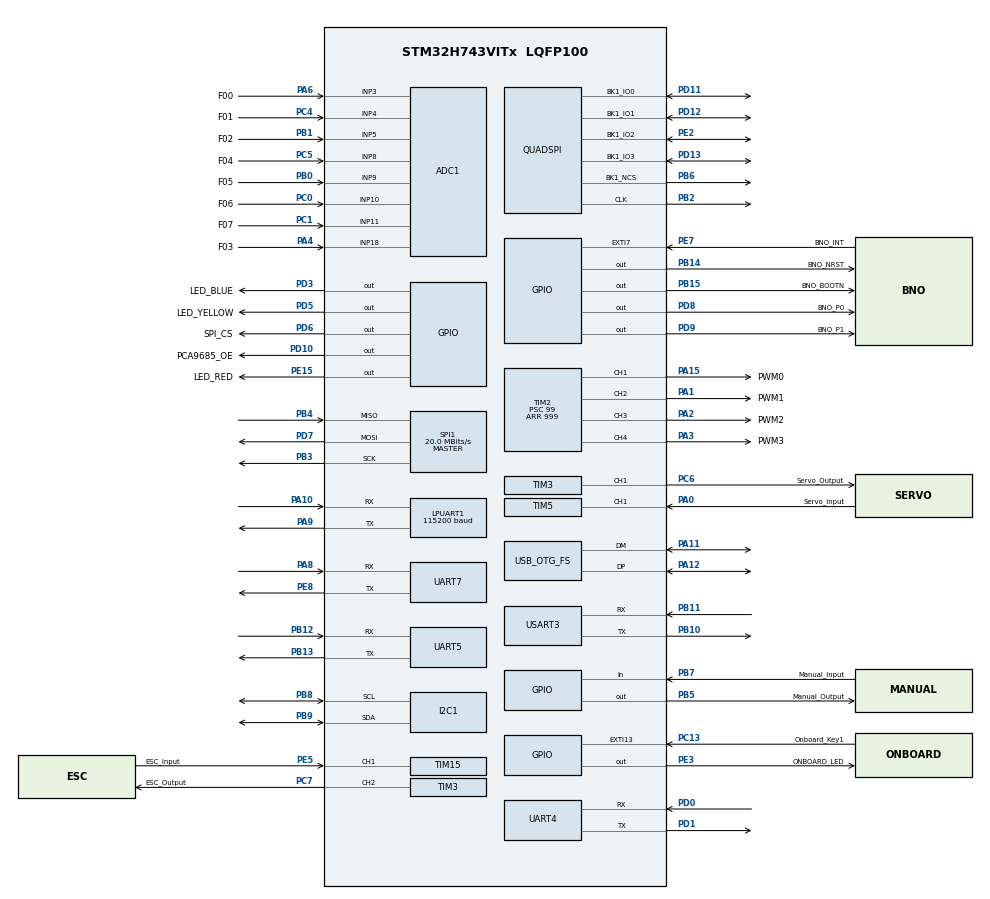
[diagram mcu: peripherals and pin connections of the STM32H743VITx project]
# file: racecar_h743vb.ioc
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ADC1.Channel-0\#ChannelRegularConversion=ADC_CHANNEL_3
ADC1.Channel-1\#ChannelRegularConversion=ADC_CHANNEL_4
ADC1.Channel-2\#ChannelRegularConversion=ADC_CHANNEL_5
ADC1.Channel-3\#ChannelRegularConversion=ADC_CHANNEL_8
ADC1.Channel-4\#ChannelRegularConversion=ADC_CHANNEL_9
ADC1.Channel-5\#ChannelRegularConversion=ADC_CHANNEL_10
ADC1.Channel-6\#ChannelRegularConversion=ADC_CHANNEL_11
ADC1.Channel-7\#ChannelRegularConversion=ADC_CHANNEL_18
ADC1.ClockPrescaler=ADC_CLOCK_ASYNC_DIV64
ADC1.ContinuousConvMode=ENABLE
ADC1.ConversionDataManagement=ADC_CONVERSIONDATA_DMA_CIRCULAR
ADC1.NbrOfConversion=8
ADC1.NbrOfConversionFlag=1
ADC1.OffsetNumber-0\#ChannelRegularConversion=ADC_OFFSET_NONE
ADC1.OffsetNumber-1\#ChannelRegularConversion=ADC_OFFSET_NONE
ADC1.OffsetNumber-2\#ChannelRegularConversion=ADC_OFFSET_NONE
ADC1.OffsetNumber-3\#ChannelRegularConversion=ADC_OFFSET_NONE
ADC1.OffsetNumber-4\#ChannelRegularConversion=ADC_OFFSET_NONE
ADC1.OffsetNumber-5\#ChannelRegularConversion=ADC_OFFSET_NONE
ADC1.OffsetNumber-6\#ChannelRegularConversion=ADC_OFFSET_NONE
ADC1.OffsetNumber-7\#ChannelRegularConversion=ADC_OFFSET_NONE
ADC1.OffsetSignedSaturation-0\#ChannelRegularConversion=DISABLE
ADC1.OffsetSignedSaturation-1\#ChannelRegularConversion=DISABLE
ADC1.OffsetSignedSaturation-2\#ChannelRegularConversion=DISABLE
ADC1.OffsetSignedSaturation-3\#ChannelRegularConversion=DISABLE
ADC1.OffsetSignedSaturation-4\#ChannelRegularConversion=DISABLE
ADC1.OffsetSignedSaturation-5\#ChannelRegularConversion=DISABLE
ADC1.OffsetSignedSaturation-6\#ChannelRegularConversion=DISABLE
ADC1.OffsetSignedSaturation-7\#ChannelRegularConversion=DISABLE
ADC1.Rank-0\#ChannelRegularConversion=1
ADC1.Rank-1\#ChannelRegularConversion=2
ADC1.Rank-2\#ChannelRegularConversion=3
ADC1.Rank-3\#ChannelRegularConversion=4
ADC1.Rank-4\#ChannelRegularConversion=5
ADC1.Rank-5\#ChannelRegularConversion=6
ADC1.Rank-6\#ChannelRegularConversion=7
ADC1.Rank-7\#ChannelRegularConversion=8
ADC1.SamplingTime-0\#ChannelRegularConversion=ADC_SAMPLETIME_387CYCLES_5
ADC1.SamplingTime-1\#ChannelRegularConversion=ADC_SAMPLETIME_387CYCLES_5
ADC1.SamplingTime-2\#ChannelRegularConversion=ADC_SAMPLETIME_387CYCLES_5
ADC1.SamplingTime-3\#ChannelRegularConversion=ADC_SAMPLETIME_387CYCLES_5
ADC1.SamplingTime-4\#ChannelRegularConversion=ADC_SAMPLETIME_387CYCLES_5
ADC1.SamplingTime-5\#ChannelRegularConversion=ADC_SAMPLETIME_387CYCLES_5
ADC1.SamplingTime-6\#ChannelRegularConversion=ADC_SAMPLETIME_387CYCLES_5
ADC1.SamplingTime-7\#ChannelRegularConversion=ADC_SAMPLETIME_387CYCLES_5
ADC1.master=1
Bdma.LPUART1_RX.0.Direction=DMA_PERIPH_TO_MEMORY
Bdma.LPUART1_RX.0.EventEnable=DISABLE
Bdma.LPUART1_RX.0.Instance=BDMA_Channel0
Bdma.LPUART1_RX.0.MemDataAlignment=DMA_MDATAALIGN_BYTE
Bdma.LPUART1_RX.0.MemInc=DMA_MINC_ENABLE
Bdma.LPUART1_RX.0.Mode=DMA_CIRCULAR
Bdma.LPUART1_RX.0.PeriphDataAlignment=DMA_PDATAALIGN_BYTE
Bdma.LPUART1_RX.0.PeriphInc=DMA_PINC_DISABLE
Bdma.LPUART1_RX.0.Polarity=HAL_DMAMUX_REQ_GEN_RISING
Bdma.LPUART1_RX.0.Priority=DMA_PRIORITY_LOW
Bdma.LPUART1_RX.0.RequestNumber=1
Bdma.LPUART1_RX.0.SignalID=NONE
Bdma.LPUART1_RX.0.SyncEnable=DISABLE
Bdma.LPUART1_RX.0.SyncPolarity=HAL_DMAMUX_SYNC_NO_EVENT
Bdma.LPUART1_RX.0.SyncRequestNumber=1
Bdma.LPUART1_RX.0.SyncSignalID=NONE
Bdma.Request0=LPUART1_RX
Bdma.RequestsNb=1
Dma.ADC1.4.Direction=DMA_PERIPH_TO_MEMORY
Dma.ADC1.4.EventEnable=DISABLE
Dma.ADC1.4.FIFOMode=DMA_FIFOMODE_DISABLE
Dma.ADC1.4.Instance=DMA1_Stream4
Dma.ADC1.4.MemDataAlignment=DMA_MDATAALIGN_HALFWORD
Dma.ADC1.4.MemInc=DMA_MINC_ENABLE
Dma.ADC1.4.Mode=DMA_CIRCULAR
Dma.ADC1.4.PeriphDataAlignment=DMA_PDATAALIGN_HALFWORD
Dma.ADC1.4.PeriphInc=DMA_PINC_DISABLE
Dma.ADC1.4.Polarity=HAL_DMAMUX_REQ_GEN_RISING
Dma.ADC1.4.Priority=DMA_PRIORITY_LOW
Dma.ADC1.4.RequestNumber=1
Dma.ADC1.4.SignalID=NONE
Dma.ADC1.4.SyncEnable=DISABLE
Dma.ADC1.4.SyncPolarity=HAL_DMAMUX_SYNC_NO_EVENT
Dma.ADC1.4.SyncRequestNumber=1
Dma.ADC1.4.SyncSignalID=NONE
Dma.Request0=UART4_RX
Dma.Request1=UART4_TX
Dma.Request2=UART5_RX
Dma.Request3=UART7_RX
Dma.Request4=ADC1
Dma.UART4_RX.0.Direction=DMA_PERIPH_TO_MEMORY
Dma.UART4_RX.0.EventEnable=DISABLE
Dma.UART4_RX.0.FIFOMode=DMA_FIFOMODE_DISABLE
Dma.UART4_RX.0.Instance=DMA1_Stream0
Dma.UART4_RX.0.MemDataAlignment=DMA_MDATAALIGN_BYTE
Dma.UART4_RX.0.MemInc=DMA_MINC_ENABLE
Dma.UART4_RX.0.Mode=DMA_NORMAL
Dma.UART4_RX.0.PeriphDataAlignment=DMA_PDATAALIGN_BYTE
Dma.UART4_RX.0.PeriphInc=DMA_PINC_DISABLE
Dma.UART4_RX.0.Polarity=HAL_DMAMUX_REQ_GEN_RISING
Dma.UART4_RX.0.Priority=DMA_PRIORITY_LOW
Dma.UART4_RX.0.RequestNumber=1
Dma.UART4_RX.0.SignalID=NONE
Dma.UART4_RX.0.SyncEnable=DISABLE
Dma.UART4_RX.0.SyncPolarity=HAL_DMAMUX_SYNC_NO_EVENT
Dma.UART4_RX.0.SyncRequestNumber=1
Dma.UART4_RX.0.SyncSignalID=NONE
Dma.UART4_TX.1.Direction=DMA_MEMORY_TO_PERIPH
Dma.UART4_TX.1.EventEnable=DISABLE
Dma.UART4_TX.1.FIFOMode=DMA_FIFOMODE_DISABLE
Dma.UART4_TX.1.Instance=DMA1_Stream1
Dma.UART4_TX.1.MemDataAlignment=DMA_MDATAALIGN_BYTE
Dma.UART4_TX.1.MemInc=DMA_MINC_ENABLE
Dma.UART4_TX.1.Mode=DMA_NORMAL
Dma.UART4_TX.1.PeriphDataAlignment=DMA_PDATAALIGN_BYTE
Dma.UART4_TX.1.PeriphInc=DMA_PINC_DISABLE
Dma.UART4_TX.1.Polarity=HAL_DMAMUX_REQ_GEN_RISING
Dma.UART4_TX.1.Priority=DMA_PRIORITY_LOW
Dma.UART4_TX.1.RequestNumber=1
Dma.UART4_TX.1.SignalID=NONE
Dma.UART4_TX.1.SyncEnable=DISABLE
Dma.UART4_TX.1.SyncPolarity=HAL_DMAMUX_SYNC_NO_EVENT
Dma.UART4_TX.1.SyncRequestNumber=1
Dma.UART4_TX.1.SyncSignalID=NONE
Dma.UART5_RX.2.Direction=DMA_PERIPH_TO_MEMORY
Dma.UART5_RX.2.EventEnable=DISABLE
Dma.UART5_RX.2.FIFOMode=DMA_FIFOMODE_DISABLE
Dma.UART5_RX.2.Instance=DMA1_Stream2
Dma.UART5_RX.2.MemDataAlignment=DMA_MDATAALIGN_BYTE
Dma.UART5_RX.2.MemInc=DMA_MINC_ENABLE
Dma.UART5_RX.2.Mode=DMA_CIRCULAR
Dma.UART5_RX.2.PeriphDataAlignment=DMA_PDATAALIGN_BYTE
Dma.UART5_RX.2.PeriphInc=DMA_PINC_DISABLE
Dma.UART5_RX.2.Polarity=HAL_DMAMUX_REQ_GEN_RISING
Dma.UART5_RX.2.Priority=DMA_PRIORITY_LOW
Dma.UART5_RX.2.RequestNumber=1
Dma.UART5_RX.2.SignalID=NONE
Dma.UART5_RX.2.SyncEnable=DISABLE
Dma.UART5_RX.2.SyncPolarity=HAL_DMAMUX_SYNC_NO_EVENT
Dma.UART5_RX.2.SyncRequestNumber=1
Dma.UART5_RX.2.SyncSignalID=NONE
Dma.UART7_RX.3.Direction=DMA_PERIPH_TO_MEMORY
Dma.UART7_RX.3.EventEnable=DISABLE
Dma.UART7_RX.3.FIFOMode=DMA_FIFOMODE_DISABLE
Dma.UART7_RX.3.Instance=DMA1_Stream3
Dma.UART7_RX.3.MemDataAlignment=DMA_MDATAALIGN_BYTE
Dma.UART7_RX.3.MemInc=DMA_MINC_ENABLE
Dma.UART7_RX.3.Mode=DMA_NORMAL
Dma.UART7_RX.3.PeriphDataAlignment=DMA_PDATAALIGN_BYTE
Dma.UART7_RX.3.PeriphInc=DMA_PINC_DISABLE
Dma.UART7_RX.3.Polarity=HAL_DMAMUX_REQ_GEN_RISING
Dma.UART7_RX.3.Priority=DMA_PRIORITY_LOW
Dma.UART7_RX.3.RequestNumber=1
Dma.UART7_RX.3.SignalID=NONE
Dma.UART7_RX.3.SyncEnable=DISABLE
Dma.UART7_RX.3.SyncPolarity=HAL_DMAMUX_SYNC_NO_EVENT
Dma.UART7_RX.3.SyncRequestNumber=1
Dma.UART7_RX.3.SyncSignalID=NONE
I2C1.Timing=0x00C0EAFF
LPUART1.BaudRate=115200
Mcu.Family=STM32H7
Mcu.Name=STM32H743VITx
Mcu.Package=LQFP100
NVIC.ADC_IRQn=true\:0\:0\:false\:false\:true\:true\:true\:true
NVIC.BDMA_Channel0_IRQn=true\:0\:0\:false\:false\:true\:false\:true\:true
NVIC.DMA1_Stream0_IRQn=true\:0\:0\:false\:false\:true\:false\:true\:true
NVIC.DMA1_Stream1_IRQn=true\:0\:0\:false\:false\:true\:false\:true\:true
NVIC.DMA1_Stream2_IRQn=true\:0\:0\:false\:false\:true\:false\:true\:true
NVIC.DMA1_Stream3_IRQn=true\:0\:0\:false\:false\:true\:false\:true\:true
NVIC.DMA1_Stream4_IRQn=true\:0\:0\:false\:false\:true\:false\:true\:true
NVIC.LPUART1_IRQn=true\:0\:0\:false\:false\:true\:true\:true\:true
NVIC.PriorityGroup=NVIC_PRIORITYGROUP_4
NVIC.TIM16_IRQn=true\:0\:0\:false\:false\:true\:true\:true\:true
NVIC.TIM7_IRQn=true\:0\:0\:false\:false\:true\:true\:true\:true
NVIC.UART4_IRQn=true\:0\:0\:false\:false\:true\:true\:true\:true
NVIC.UART5_IRQn=true\:0\:0\:false\:false\:true\:true\:true\:true
NVIC.UART7_IRQn=true\:0\:0\:false\:false\:true\:true\:true\:true
PA0.GPIO_Label=Servo_Input
PA0.Signal=S_TIM5_CH1
PA1.GPIO_Label=PWM1
PA1.Signal=S_TIM2_CH2
PA10.Mode=Asynchronous
PA10.Signal=LPUART1_RX
PA11.Mode=Device_Only
PA11.Signal=USB_OTG_FS_DM
PA12.Mode=Device_Only
PA12.Signal=USB_OTG_FS_DP
PA13\ (JTMS/SWDIO).Mode=Serial_Wire
PA13\ (JTMS/SWDIO).Signal=DEBUG_JTMS-SWDIO
PA14\ (JTCK/SWCLK).Mode=Serial_Wire
PA14\ (JTCK/SWCLK).Signal=DEBUG_JTCK-SWCLK
PA15\ (JTDI).GPIO_Label=PWM0
PA15\ (JTDI).Signal=S_TIM2_CH1_ETR
PA2.GPIO_Label=PWM2
PA2.Signal=S_TIM2_CH3
PA3.GPIO_Label=PWM3
PA3.Signal=S_TIM2_CH4
PA4.GPIO_Label=F03
PA4.Signal=ADCx_INP18
PA6.GPIO_Label=F00
PA6.Signal=ADCx_INP3
PA8.Mode=Asynchronous
PA8.Signal=UART7_RX
PA9.Mode=Asynchronous
PA9.Signal=LPUART1_TX
PB0.GPIO_Label=F05
PB0.Signal=ADCx_INP9
PB1.GPIO_Label=F02
PB1.Signal=ADCx_INP5
PB10.Mode=Asynchronous
PB10.Signal=USART3_TX
PB11.Mode=Asynchronous
PB11.Signal=USART3_RX
PB12.Mode=Asynchronous
PB12.Signal=UART5_RX
PB13.Mode=Asynchronous
PB13.Signal=UART5_TX
PB14.GPIO_Label=BNO_NRST
PB14.Signal=GPIO_Output
PB15.GPIO_Label=BNO_BOOTN
PB15.Signal=GPIO_Output
PB2.Mode=Single Bank 1
PB2.Signal=QUADSPI_CLK
PB3\ (JTDO/TRACESWO).Mode=Full_Duplex_Master
PB3\ (JTDO/TRACESWO).Signal=SPI1_SCK
PB4\ (NJTRST).Mode=Full_Duplex_Master
PB4\ (NJTRST).Signal=SPI1_MISO
PB5.GPIO_Label=Manual_Output
PB5.Signal=GPIO_Output
PB6.Mode=Single Bank 1
PB6.Signal=QUADSPI_BK1_NCS
PB7.GPIO_Label=Manual_Input
PB7.Signal=GPIO_Input
PB8.Mode=I2C
PB8.Signal=I2C1_SCL
PB9.Mode=I2C
PB9.Signal=I2C1_SDA
PC0.GPIO_Label=F06
PC0.Signal=ADCx_INP10
PC1.GPIO_Label=F07
PC1.Signal=ADCx_INP11
PC13.GPIO_Label=Onboard_Key1
PC13.Signal=GPXTI13
PC14-OSC32_IN\ (OSC32_IN).Mode=LSE-External-Oscillator
PC14-OSC32_IN\ (OSC32_IN).Signal=RCC_OSC32_IN
PC15-OSC32_OUT\ (OSC32_OUT).Mode=LSE-External-Oscillator
PC15-OSC32_OUT\ (OSC32_OUT).Signal=RCC_OSC32_OUT
PC4.GPIO_Label=F01
PC4.Signal=ADCx_INP4
PC5.GPIO_Label=F04
PC5.Signal=ADCx_INP8
PC6.GPIO_Label=Servo_Output
PC6.Signal=S_TIM3_CH1
PC7.GPIO_Label=ESC_Output
PC7.Signal=S_TIM3_CH2
PD0.Mode=Asynchronous
PD0.Signal=UART4_RX
PD1.Mode=Asynchronous
PD1.Signal=UART4_TX
PD10.GPIO_Label=PCA9685_OE
PD10.Signal=GPIO_Output
PD11.Mode=Single Bank 1
PD11.Signal=QUADSPI_BK1_IO0
PD12.Mode=Single Bank 1
PD12.Signal=QUADSPI_BK1_IO1
PD13.Mode=Single Bank 1
PD13.Signal=QUADSPI_BK1_IO3
PD3.GPIO_Label=LED_BLUE
PD3.Signal=GPIO_Output
PD5.GPIO_Label=LED_YELLOW
PD5.Signal=GPIO_Output
PD6.GPIO_Label=SPI_CS
PD6.Signal=GPIO_Output
PD7.Mode=Full_Duplex_Master
PD7.Signal=SPI1_MOSI
PD8.GPIO_Label=BNO_P0
PD8.Signal=GPIO_Output
PD9.GPIO_Label=BNO_P1
PD9.Signal=GPIO_Output
PE15.GPIO_Label=LED_RED
PE15.Signal=GPIO_Output
PE2.Mode=Single Bank 1
PE2.Signal=QUADSPI_BK1_IO2
PE3.GPIO_Label=ONBOARD_LED
PE3.Signal=GPIO_Output
PE5.GPIO_Label=ESC_Input
PE5.Signal=S_TIM15_CH1
PE7.GPIO_Label=BNO_INT
PE7.Signal=GPXTI7
PE8.Mode=Asynchronous
PE8.Signal=UART7_TX
PH0-OSC_IN\ (PH0).Mode=HSE-External-Oscillator
PH0-OSC_IN\ (PH0).Signal=RCC_OSC_IN
PH1-OSC_OUT\ (PH1).Mode=HSE-External-Oscillator
PH1-OSC_OUT\ (PH1).Signal=RCC_OSC_OUT
ProjectManager.HeapSize=0x200
ProjectManager.StackSize=0x400
ProjectManager.TargetToolchain=STM32CubeIDE
QUADSPI.ChipSelectHighTime=QSPI_CS_HIGH_TIME_5_CYCLE
QUADSPI.ClockPrescaler=10
QUADSPI.FlashSize=22
QUADSPI.SampleShifting=QSPI_SAMPLE_SHIFTING_HALFCYCLE
RCC.ADCCLockSelection=RCC_ADCCLKSOURCE_CLKP
RCC.ADCFreq_Value=64000000
RCC.APB1Freq_Value=50000000
RCC.APB2Freq_Value=100000000
RCC.APB3Freq_Value=100000000
RCC.APB4Freq_Value=50000000
RCC.CortexFreq_Value=400000000
RCC.D1PPRE=RCC_APB3_DIV2
RCC.D2PPRE1=RCC_APB1_DIV4
RCC.D2PPRE2=RCC_APB2_DIV2
RCC.D3PPRE=RCC_APB4_DIV4
RCC.DIVM1=5
RCC.DIVM2=10
RCC.DIVN1=160
RCC.DIVN2=60
RCC.DIVN3=128
RCC.DIVQ1=20
RCC.DIVQ2=4
RCC.HCLKFreq_Value=200000000
RCC.HPRE=RCC_HCLK_DIV2
RCC.PLL2FRACN=0
RCC.PLL2_VCI_Range-AdvancedSettings=RCC_PLL2VCIRANGE_0
RCC.PLL3FRACN=0
RCC.PLL3_VCI_Range-AdvancedSettings=RCC_PLL3VCIRANGE_3
RCC.PLLFRACN=0
RCC.PLLSourceVirtual=RCC_PLLSOURCE_HSE
RCC.SDMMC1CLockSelection=RCC_SDMMCCLKSOURCE_PLL2
RCC.SYSCLKFreq_VALUE=400000000
RCC.SYSCLKSource=RCC_SYSCLKSOURCE_PLLCLK
RCC.Tim2Mul=1
RCC.USBFreq_Value=40000000
SH.ADCx_INP10.0=ADC1_INP10,IN10-Single-Ended
SH.ADCx_INP11.0=ADC1_INP11,IN11-Single-Ended
SH.ADCx_INP18.0=ADC1_INP18,IN18-Single-Ended
SH.ADCx_INP3.0=ADC1_INP3,IN3-Single-Ended
SH.ADCx_INP4.0=ADC1_INP4,IN4-Single-Ended
SH.ADCx_INP5.0=ADC1_INP5,IN5-Single-Ended
SH.ADCx_INP8.0=ADC1_INP8,IN8-Single-Ended
SH.ADCx_INP9.0=ADC1_INP9,IN9-Single-Ended
SH.S_TIM15_CH1.0=TIM15_CH1,PWM_Input_1
SH.S_TIM2_CH1_ETR.0=TIM2_CH1,PWM Generation1 CH1
SH.S_TIM2_CH2.0=TIM2_CH2,PWM Generation2 CH2
SH.S_TIM2_CH3.0=TIM2_CH3,PWM Generation3 CH3
SH.S_TIM2_CH4.0=TIM2_CH4,PWM Generation4 CH4
SH.S_TIM3_CH1.0=TIM3_CH1,PWM Generation1 CH1
SH.S_TIM3_CH2.0=TIM3_CH2,PWM Generation2 CH2
SH.S_TIM5_CH1.0=TIM5_CH1,PWM_Input_1
SPI1.BaudRatePrescaler=SPI_BAUDRATEPRESCALER_2
SPI1.CalculateBaudRate=20.0 MBits/s
SPI1.Direction=SPI_DIRECTION_2LINES
SPI1.Mode=SPI_MODE_MASTER
SPI1.VirtualType=VM_MASTER
TIM16.AutoReloadPreload=TIM_AUTORELOAD_PRELOAD_ENABLE
TIM16.Period=499
TIM16.Prescaler=9999
TIM2.Channel-PWM\ Generation1\ CH1=TIM_CHANNEL_1
TIM2.Channel-PWM\ Generation2\ CH2=TIM_CHANNEL_2
TIM2.Channel-PWM\ Generation3\ CH3=TIM_CHANNEL_3
TIM2.Channel-PWM\ Generation4\ CH4=TIM_CHANNEL_4
TIM2.Period=999
TIM2.Prescaler=99
TIM3.AutoReloadPreload=TIM_AUTORELOAD_PRELOAD_ENABLE
TIM3.Channel-PWM\ Generation1\ CH1=TIM_CHANNEL_1
TIM3.Channel-PWM\ Generation2\ CH2=TIM_CHANNEL_2
TIM3.Period=15503
TIM3.Prescaler=99
TIM7.AutoReloadPreload=TIM_AUTORELOAD_PRELOAD_ENABLE
TIM7.Period=999
TIM7.Prescaler=9999
USART3.VirtualMode-Asynchronous=VM_ASYNC
USB_OTG_FS.VirtualMode=Device_Only
VP_TIM16_VS_ClockSourceINT.Mode=Enable_Timer
VP_TIM7_VS_ClockSourceINT.Mode=Enable_Timer
board=custom

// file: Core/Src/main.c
/* USER CODE BEGIN Header */
/**
  ******************************************************************************
  * @file           : main.c
  * @brief          : Main program body
  ******************************************************************************
  * @attention
  *
  * Copyright (c) 2023 STMicroelectronics.
  * All rights reserved.
  *
  * This software is licensed under terms that can be found in the LICENSE file
  * in the root directory of this software component.
  * If no LICENSE file comes with this software, it is provided AS-IS.
  *
  ******************************************************************************
  */
/* USER CODE END Header */
#include "main.h"

/* USER CODE BEGIN Includes */
#include "mainpp.h"
/* USER CODE END Includes */

ADC_HandleTypeDef hadc1;
DMA_HandleTypeDef hdma_adc1;

I2C_HandleTypeDef hi2c1;

UART_HandleTypeDef hlpuart1;
UART_HandleTypeDef huart4;
UART_HandleTypeDef huart5;
UART_HandleTypeDef huart7;
UART_HandleTypeDef huart3;
DMA_HandleTypeDef hdma_lpuart1_rx;
DMA_HandleTypeDef hdma_uart4_rx;
DMA_HandleTypeDef hdma_uart4_tx;
DMA_HandleTypeDef hdma_uart5_rx;
DMA_HandleTypeDef hdma_uart7_rx;

QSPI_HandleTypeDef hqspi;

SPI_HandleTypeDef hspi1;

TIM_HandleTypeDef htim2;
TIM_HandleTypeDef htim3;
TIM_HandleTypeDef htim5;
TIM_HandleTypeDef htim7;
TIM_HandleTypeDef htim15;
TIM_HandleTypeDef htim16;

PCD_HandleTypeDef hpcd_USB_OTG_FS;

void SystemClock_Config(void);
void PeriphCommonClock_Config(void);
static void MX_GPIO_Init(void);
static void MX_BDMA_Init(void);
static void MX_DMA_Init(void);
static void MX_ADC1_Init(void);
static void MX_I2C1_Init(void);
static void MX_LPUART1_UART_Init(void);
static void MX_UART4_Init(void);
static void MX_UART5_Init(void);
static void MX_UART7_Init(void);
static void MX_USART3_UART_Init(void);
static void MX_QUADSPI_Init(void);
static void MX_SPI1_Init(void);
static void MX_TIM5_Init(void);
static void MX_TIM2_Init(void);
static void MX_USB_OTG_FS_PCD_Init(void);
static void MX_TIM3_Init(void);
static void MX_TIM15_Init(void);
static void MX_TIM7_Init(void);
static void MX_TIM16_Init(void);

int main(void)
{

  /* MCU Configuration--------------------------------------------------------*/

  /* Reset of all peripherals, Initializes the Flash interface and the Systick. */
  HAL_Init();

  /* Configure the system clock */
  SystemClock_Config();

/* Configure the peripherals common clocks */
  PeriphCommonClock_Config();

  /* Initialize all configured peripherals */
  MX_GPIO_Init();
  MX_BDMA_Init();
  MX_DMA_Init();
  MX_ADC1_Init();
  MX_I2C1_Init();
  MX_LPUART1_UART_Init();
  MX_UART4_Init();
  MX_UART5_Init();
  MX_UART7_Init();
  MX_USART3_UART_Init();
  MX_QUADSPI_Init();
  MX_SPI1_Init();
  MX_TIM5_Init();
  MX_TIM2_Init();
  MX_USB_OTG_FS_PCD_Init();
  MX_TIM3_Init();
  MX_TIM15_Init();
  MX_TIM7_Init();
  MX_TIM16_Init();
  /* USER CODE BEGIN 2 */

  setup();
  /* USER CODE END 2 */

  /* Infinite loop */
  /* USER CODE BEGIN WHILE */
  while (1)
  {
	  loop();
    /* USER CODE END WHILE */

  }
}

void SystemClock_Config(void)
{
  RCC_OscInitTypeDef RCC_OscInitStruct = {0};
  RCC_ClkInitTypeDef RCC_ClkInitStruct = {0};

  /** Supply configuration update enable
  */
  HAL_PWREx_ConfigSupply(PWR_LDO_SUPPLY);

  /** Configure the main internal regulator output voltage
  */
  __HAL_PWR_VOLTAGESCALING_CONFIG(PWR_REGULATOR_VOLTAGE_SCALE1);

  while(!__HAL_PWR_GET_FLAG(PWR_FLAG_VOSRDY)) {}

  /** Initializes the RCC Oscillators according to the specified parameters
  * in the RCC_OscInitTypeDef structure.
  */
  RCC_OscInitStruct.OscillatorType = RCC_OSCILLATORTYPE_HSI|RCC_OSCILLATORTYPE_HSE;
  RCC_OscInitStruct.HSEState = RCC_HSE_ON;
  RCC_OscInitStruct.HSIState = RCC_HSI_DIV1;
  RCC_OscInitStruct.HSICalibrationValue = RCC_HSICALIBRATION_DEFAULT;
  RCC_OscInitStruct.PLL.PLLState = RCC_PLL_ON;
  RCC_OscInitStruct.PLL.PLLSource = RCC_PLLSOURCE_HSE;
  RCC_OscInitStruct.PLL.PLLM = 5;
  RCC_OscInitStruct.PLL.PLLN = 160;
  RCC_OscInitStruct.PLL.PLLP = 2;
  RCC_OscInitStruct.PLL.PLLQ = 20;
  RCC_OscInitStruct.PLL.PLLR = 2;
  RCC_OscInitStruct.PLL.PLLRGE = RCC_PLL1VCIRANGE_2;
  RCC_OscInitStruct.PLL.PLLVCOSEL = RCC_PLL1VCOWIDE;
  RCC_OscInitStruct.PLL.PLLFRACN = 0;
  if (HAL_RCC_OscConfig(&RCC_OscInitStruct) != HAL_OK)
  {
    Error_Handler();
  }

  /** Initializes the CPU, AHB and APB buses clocks
  */
  RCC_ClkInitStruct.ClockType = RCC_CLOCKTYPE_HCLK|RCC_CLOCKTYPE_SYSCLK
                              |RCC_CLOCKTYPE_PCLK1|RCC_CLOCKTYPE_PCLK2
                              |RCC_CLOCKTYPE_D3PCLK1|RCC_CLOCKTYPE_D1PCLK1;
  RCC_ClkInitStruct.SYSCLKSource = RCC_SYSCLKSOURCE_PLLCLK;
  RCC_ClkInitStruct.SYSCLKDivider = RCC_SYSCLK_DIV1;
  RCC_ClkInitStruct.AHBCLKDivider = RCC_HCLK_DIV2;
  RCC_ClkInitStruct.APB3CLKDivider = RCC_APB3_DIV2;
  RCC_ClkInitStruct.APB1CLKDivider = RCC_APB1_DIV4;
  RCC_ClkInitStruct.APB2CLKDivider = RCC_APB2_DIV2;
  RCC_ClkInitStruct.APB4CLKDivider = RCC_APB4_DIV4;

  if (HAL_RCC_ClockConfig(&RCC_ClkInitStruct, FLASH_LATENCY_2) != HAL_OK)
  {
    Error_Handler();
  }
}

void PeriphCommonClock_Config(void)
{
  RCC_PeriphCLKInitTypeDef PeriphClkInitStruct = {0};

  /** Initializes the peripherals clock
  */
  PeriphClkInitStruct.PeriphClockSelection = RCC_PERIPHCLK_CKPER;
  PeriphClkInitStruct.CkperClockSelection = RCC_CLKPSOURCE_HSI;
  if (HAL_RCCEx_PeriphCLKConfig(&PeriphClkInitStruct) != HAL_OK)
  {
    Error_Handler();
  }
}

static void MX_ADC1_Init(void)
{

  ADC_MultiModeTypeDef multimode = {0};
  ADC_ChannelConfTypeDef sConfig = {0};

  /** Common config
  */
  hadc1.Instance = ADC1;
  hadc1.Init.ClockPrescaler = ADC_CLOCK_ASYNC_DIV64;
  hadc1.Init.Resolution = ADC_RESOLUTION_16B;
  hadc1.Init.ScanConvMode = ADC_SCAN_ENABLE;
  hadc1.Init.EOCSelection = ADC_EOC_SINGLE_CONV;
  hadc1.Init.LowPowerAutoWait = DISABLE;
  hadc1.Init.ContinuousConvMode = ENABLE;
  hadc1.Init.NbrOfConversion = 8;
  hadc1.Init.DiscontinuousConvMode = DISABLE;
  hadc1.Init.ExternalTrigConv = ADC_SOFTWARE_START;
  hadc1.Init.ExternalTrigConvEdge = ADC_EXTERNALTRIGCONVEDGE_NONE;
  hadc1.Init.ConversionDataManagement = ADC_CONVERSIONDATA_DMA_CIRCULAR;
  hadc1.Init.Overrun = ADC_OVR_DATA_PRESERVED;
  hadc1.Init.LeftBitShift = ADC_LEFTBITSHIFT_NONE;
  hadc1.Init.OversamplingMode = DISABLE;
  if (HAL_ADC_Init(&hadc1) != HAL_OK)
  {
    Error_Handler();
  }

  /** Configure the ADC multi-mode
  */
  multimode.Mode = ADC_MODE_INDEPENDENT;
  if (HAL_ADCEx_MultiModeConfigChannel(&hadc1, &multimode) != HAL_OK)
  {
    Error_Handler();
  }

  /** Configure Regular Channel
  */
  sConfig.Channel = ADC_CHANNEL_3;
  sConfig.Rank = ADC_REGULAR_RANK_1;
  sConfig.SamplingTime = ADC_SAMPLETIME_387CYCLES_5;
  sConfig.SingleDiff = ADC_SINGLE_ENDED;
  sConfig.OffsetNumber = ADC_OFFSET_NONE;
  sConfig.Offset = 0;
  sConfig.OffsetSignedSaturation = DISABLE;
  if (HAL_ADC_ConfigChannel(&hadc1, &sConfig) != HAL_OK)
  {
    Error_Handler();
  }

  /** Configure Regular Channel
  */
  sConfig.Channel = ADC_CHANNEL_4;
  sConfig.Rank = ADC_REGULAR_RANK_2;
  if (HAL_ADC_ConfigChannel(&hadc1, &sConfig) != HAL_OK)
  {
    Error_Handler();
  }

  /** Configure Regular Channel
  */
  sConfig.Channel = ADC_CHANNEL_5;
  sConfig.Rank = ADC_REGULAR_RANK_3;
  if (HAL_ADC_ConfigChannel(&hadc1, &sConfig) != HAL_OK)
  {
    Error_Handler();
  }

  /** Configure Regular Channel
  */
  sConfig.Channel = ADC_CHANNEL_8;
  sConfig.Rank = ADC_REGULAR_RANK_4;
  if (HAL_ADC_ConfigChannel(&hadc1, &sConfig) != HAL_OK)
  {
    Error_Handler();
  }

  /** Configure Regular Channel
  */
  sConfig.Channel = ADC_CHANNEL_9;
  sConfig.Rank = ADC_REGULAR_RANK_5;
  if (HAL_ADC_ConfigChannel(&hadc1, &sConfig) != HAL_OK)
  {
    Error_Handler();
  }

  /** Configure Regular Channel
  */
  sConfig.Channel = ADC_CHANNEL_10;
  sConfig.Rank = ADC_REGULAR_RANK_6;
  if (HAL_ADC_ConfigChannel(&hadc1, &sConfig) != HAL_OK)
  {
    Error_Handler();
  }

  /** Configure Regular Channel
  */
  sConfig.Channel = ADC_CHANNEL_11;
  sConfig.Rank = ADC_REGULAR_RANK_7;
  if (HAL_ADC_ConfigChannel(&hadc1, &sConfig) != HAL_OK)
  {
    Error_Handler();
  }

  /** Configure Regular Channel
  */
  sConfig.Channel = ADC_CHANNEL_18;
  sConfig.Rank = ADC_REGULAR_RANK_8;
  if (HAL_ADC_ConfigChannel(&hadc1, &sConfig) != HAL_OK)
  {
    Error_Handler();
  }

}

static void MX_I2C1_Init(void)
{

  hi2c1.Instance = I2C1;
  hi2c1.Init.Timing = 0x00C0EAFF;
  hi2c1.Init.OwnAddress1 = 0;
  hi2c1.Init.AddressingMode = I2C_ADDRESSINGMODE_7BIT;
  hi2c1.Init.DualAddressMode = I2C_DUALADDRESS_DISABLE;
  hi2c1.Init.OwnAddress2 = 0;
  hi2c1.Init.OwnAddress2Masks = I2C_OA2_NOMASK;
  hi2c1.Init.GeneralCallMode = I2C_GENERALCALL_DISABLE;
  hi2c1.Init.NoStretchMode = I2C_NOSTRETCH_DISABLE;
  if (HAL_I2C_Init(&hi2c1) != HAL_OK)
  {
    Error_Handler();
  }

  /** Configure Analogue filter
  */
  if (HAL_I2CEx_ConfigAnalogFilter(&hi2c1, I2C_ANALOGFILTER_ENABLE) != HAL_OK)
  {
    Error_Handler();
  }

  /** Configure Digital filter
  */
  if (HAL_I2CEx_ConfigDigitalFilter(&hi2c1, 0) != HAL_OK)
  {
    Error_Handler();
  }

}

static void MX_LPUART1_UART_Init(void)
{

  hlpuart1.Instance = LPUART1;
  hlpuart1.Init.BaudRate = 115200;
  hlpuart1.Init.WordLength = UART_WORDLENGTH_8B;
  hlpuart1.Init.StopBits = UART_STOPBITS_1;
  hlpuart1.Init.Parity = UART_PARITY_NONE;
  hlpuart1.Init.Mode = UART_MODE_TX_RX;
  hlpuart1.Init.HwFlowCtl = UART_HWCONTROL_NONE;
  hlpuart1.Init.OneBitSampling = UART_ONE_BIT_SAMPLE_DISABLE;
  hlpuart1.Init.ClockPrescaler = UART_PRESCALER_DIV1;
  hlpuart1.AdvancedInit.AdvFeatureInit = UART_ADVFEATURE_NO_INIT;
  hlpuart1.FifoMode = UART_FIFOMODE_DISABLE;
  if (HAL_UART_Init(&hlpuart1) != HAL_OK)
  {
    Error_Handler();
  }
  if (HAL_UARTEx_SetTxFifoThreshold(&hlpuart1, UART_TXFIFO_THRESHOLD_1_8) != HAL_OK)
  {
    Error_Handler();
  }
  if (HAL_UARTEx_SetRxFifoThreshold(&hlpuart1, UART_RXFIFO_THRESHOLD_1_8) != HAL_OK)
  {
    Error_Handler();
  }
  if (HAL_UARTEx_DisableFifoMode(&hlpuart1) != HAL_OK)
  {
    Error_Handler();
  }

}

static void MX_UART4_Init(void)
{

  huart4.Instance = UART4;
  huart4.Init.BaudRate = 115200;
  huart4.Init.WordLength = UART_WORDLENGTH_8B;
  huart4.Init.StopBits = UART_STOPBITS_1;
  huart4.Init.Parity = UART_PARITY_NONE;
  huart4.Init.Mode = UART_MODE_TX_RX;
  huart4.Init.HwFlowCtl = UART_HWCONTROL_NONE;
  huart4.Init.OverSampling = UART_OVERSAMPLING_16;
  huart4.Init.OneBitSampling = UART_ONE_BIT_SAMPLE_DISABLE;
  huart4.Init.ClockPrescaler = UART_PRESCALER_DIV1;
  huart4.AdvancedInit.AdvFeatureInit = UART_ADVFEATURE_NO_INIT;
  if (HAL_UART_Init(&huart4) != HAL_OK)
  {
    Error_Handler();
  }
  if (HAL_UARTEx_SetTxFifoThreshold(&huart4, UART_TXFIFO_THRESHOLD_1_8) != HAL_OK)
  {
    Error_Handler();
  }
  if (HAL_UARTEx_SetRxFifoThreshold(&huart4, UART_RXFIFO_THRESHOLD_1_8) != HAL_OK)
  {
    Error_Handler();
  }
  if (HAL_UARTEx_DisableFifoMode(&huart4) != HAL_OK)
  {
    Error_Handler();
  }

}

static void MX_UART5_Init(void)
{

  huart5.Instance = UART5;
  huart5.Init.BaudRate = 115200;
  huart5.Init.WordLength = UART_WORDLENGTH_8B;
  huart5.Init.StopBits = UART_STOPBITS_1;
  huart5.Init.Parity = UART_PARITY_NONE;
  huart5.Init.Mode = UART_MODE_TX_RX;
  huart5.Init.HwFlowCtl = UART_HWCONTROL_NONE;
  huart5.Init.OverSampling = UART_OVERSAMPLING_16;
  huart5.Init.OneBitSampling = UART_ONE_BIT_SAMPLE_DISABLE;
  huart5.Init.ClockPrescaler = UART_PRESCALER_DIV1;
  huart5.AdvancedInit.AdvFeatureInit = UART_ADVFEATURE_NO_INIT;
  if (HAL_UART_Init(&huart5) != HAL_OK)
  {
    Error_Handler();
  }
  if (HAL_UARTEx_SetTxFifoThreshold(&huart5, UART_TXFIFO_THRESHOLD_1_8) != HAL_OK)
  {
    Error_Handler();
  }
  if (HAL_UARTEx_SetRxFifoThreshold(&huart5, UART_RXFIFO_THRESHOLD_1_8) != HAL_OK)
  {
    Error_Handler();
  }
  if (HAL_UARTEx_DisableFifoMode(&huart5) != HAL_OK)
  {
    Error_Handler();
  }

}

static void MX_UART7_Init(void)
{

  huart7.Instance = UART7;
  huart7.Init.BaudRate = 115200;
  huart7.Init.WordLength = UART_WORDLENGTH_8B;
  huart7.Init.StopBits = UART_STOPBITS_1;
  huart7.Init.Parity = UART_PARITY_NONE;
  huart7.Init.Mode = UART_MODE_TX_RX;
  huart7.Init.HwFlowCtl = UART_HWCONTROL_NONE;
  huart7.Init.OverSampling = UART_OVERSAMPLING_16;
  huart7.Init.OneBitSampling = UART_ONE_BIT_SAMPLE_DISABLE;
  huart7.Init.ClockPrescaler = UART_PRESCALER_DIV1;
  huart7.AdvancedInit.AdvFeatureInit = UART_ADVFEATURE_NO_INIT;
  if (HAL_UART_Init(&huart7) != HAL_OK)
  {
    Error_Handler();
  }
  if (HAL_UARTEx_SetTxFifoThreshold(&huart7, UART_TXFIFO_THRESHOLD_1_8) != HAL_OK)
  {
    Error_Handler();
  }
  if (HAL_UARTEx_SetRxFifoThreshold(&huart7, UART_RXFIFO_THRESHOLD_1_8) != HAL_OK)
  {
    Error_Handler();
  }
  if (HAL_UARTEx_DisableFifoMode(&huart7) != HAL_OK)
  {
    Error_Handler();
  }

}

static void MX_USART3_UART_Init(void)
{

  huart3.Instance = USART3;
  huart3.Init.BaudRate = 115200;
  huart3.Init.WordLength = UART_WORDLENGTH_8B;
  huart3.Init.StopBits = UART_STOPBITS_1;
  huart3.Init.Parity = UART_PARITY_NONE;
  huart3.Init.Mode = UART_MODE_TX_RX;
  huart3.Init.HwFlowCtl = UART_HWCONTROL_NONE;
  huart3.Init.OverSampling = UART_OVERSAMPLING_16;
  huart3.Init.OneBitSampling = UART_ONE_BIT_SAMPLE_DISABLE;
  huart3.Init.ClockPrescaler = UART_PRESCALER_DIV1;
  huart3.AdvancedInit.AdvFeatureInit = UART_ADVFEATURE_NO_INIT;
  if (HAL_UART_Init(&huart3) != HAL_OK)
  {
    Error_Handler();
  }
  if (HAL_UARTEx_SetTxFifoThreshold(&huart3, UART_TXFIFO_THRESHOLD_1_8) != HAL_OK)
  {
    Error_Handler();
  }
  if (HAL_UARTEx_SetRxFifoThreshold(&huart3, UART_RXFIFO_THRESHOLD_1_8) != HAL_OK)
  {
    Error_Handler();
  }
  if (HAL_UARTEx_DisableFifoMode(&huart3) != HAL_OK)
  {
    Error_Handler();
  }

}

static void MX_QUADSPI_Init(void)
{

  /* QUADSPI parameter configuration*/
  hqspi.Instance = QUADSPI;
  hqspi.Init.ClockPrescaler = 10;
  hqspi.Init.FifoThreshold = 1;
  hqspi.Init.SampleShifting = QSPI_SAMPLE_SHIFTING_HALFCYCLE;
  hqspi.Init.FlashSize = 22;
  hqspi.Init.ChipSelectHighTime = QSPI_CS_HIGH_TIME_5_CYCLE;
  hqspi.Init.ClockMode = QSPI_CLOCK_MODE_0;
  hqspi.Init.FlashID = QSPI_FLASH_ID_1;
  hqspi.Init.DualFlash = QSPI_DUALFLASH_DISABLE;
  if (HAL_QSPI_Init(&hqspi) != HAL_OK)
  {
    Error_Handler();
  }

}

static void MX_SPI1_Init(void)
{

  /* SPI1 parameter configuration*/
  hspi1.Instance = SPI1;
  hspi1.Init.Mode = SPI_MODE_MASTER;
  hspi1.Init.Direction = SPI_DIRECTION_2LINES;
  hspi1.Init.DataSize = SPI_DATASIZE_4BIT;
  hspi1.Init.CLKPolarity = SPI_POLARITY_LOW;
  hspi1.Init.CLKPhase = SPI_PHASE_1EDGE;
  hspi1.Init.NSS = SPI_NSS_SOFT;
  hspi1.Init.BaudRatePrescaler = SPI_BAUDRATEPRESCALER_2;
  hspi1.Init.FirstBit = SPI_FIRSTBIT_MSB;
  hspi1.Init.TIMode = SPI_TIMODE_DISABLE;
  hspi1.Init.CRCCalculation = SPI_CRCCALCULATION_DISABLE;
  hspi1.Init.CRCPolynomial = 0x0;
  hspi1.Init.NSSPMode = SPI_NSS_PULSE_ENABLE;
  hspi1.Init.NSSPolarity = SPI_NSS_POLARITY_LOW;
  hspi1.Init.FifoThreshold = SPI_FIFO_THRESHOLD_01DATA;
  hspi1.Init.TxCRCInitializationPattern = SPI_CRC_INITIALIZATION_ALL_ZERO_PATTERN;
  hspi1.Init.RxCRCInitializationPattern = SPI_CRC_INITIALIZATION_ALL_ZERO_PATTERN;
  hspi1.Init.MasterSSIdleness = SPI_MASTER_SS_IDLENESS_00CYCLE;
  hspi1.Init.MasterInterDataIdleness = SPI_MASTER_INTERDATA_IDLENESS_00CYCLE;
  hspi1.Init.MasterReceiverAutoSusp = SPI_MASTER_RX_AUTOSUSP_DISABLE;
  hspi1.Init.MasterKeepIOState = SPI_MASTER_KEEP_IO_STATE_DISABLE;
  hspi1.Init.IOSwap = SPI_IO_SWAP_DISABLE;
  if (HAL_SPI_Init(&hspi1) != HAL_OK)
  {
    Error_Handler();
  }

}

static void MX_TIM2_Init(void)
{

  TIM_MasterConfigTypeDef sMasterConfig = {0};
  TIM_OC_InitTypeDef sConfigOC = {0};

  htim2.Instance = TIM2;
  htim2.Init.Prescaler = 99;
  htim2.Init.CounterMode = TIM_COUNTERMODE_UP;
  htim2.Init.Period = 999;
  htim2.Init.ClockDivision = TIM_CLOCKDIVISION_DIV1;
  htim2.Init.AutoReloadPreload = TIM_AUTORELOAD_PRELOAD_DISABLE;
  if (HAL_TIM_PWM_Init(&htim2) != HAL_OK)
  {
    Error_Handler();
  }
  sMasterConfig.MasterOutputTrigger = TIM_TRGO_RESET;
  sMasterConfig.MasterSlaveMode = TIM_MASTERSLAVEMODE_DISABLE;
  if (HAL_TIMEx_MasterConfigSynchronization(&htim2, &sMasterConfig) != HAL_OK)
  {
    Error_Handler();
  }
  sConfigOC.OCMode = TIM_OCMODE_PWM1;
  sConfigOC.Pulse = 0;
  sConfigOC.OCPolarity = TIM_OCPOLARITY_HIGH;
  sConfigOC.OCFastMode = TIM_OCFAST_DISABLE;
  if (HAL_TIM_PWM_ConfigChannel(&htim2, &sConfigOC, TIM_CHANNEL_1) != HAL_OK)
  {
    Error_Handler();
  }
  if (HAL_TIM_PWM_ConfigChannel(&htim2, &sConfigOC, TIM_CHANNEL_2) != HAL_OK)
  {
    Error_Handler();
  }
  if (HAL_TIM_PWM_ConfigChannel(&htim2, &sConfigOC, TIM_CHANNEL_3) != HAL_OK)
  {
    Error_Handler();
  }
  if (HAL_TIM_PWM_ConfigChannel(&htim2, &sConfigOC, TIM_CHANNEL_4) != HAL_OK)
  {
    Error_Handler();
  }
  HAL_TIM_MspPostInit(&htim2);

}

static void MX_TIM3_Init(void)
{

  TIM_MasterConfigTypeDef sMasterConfig = {0};
  TIM_OC_InitTypeDef sConfigOC = {0};

  htim3.Instance = TIM3;
  htim3.Init.Prescaler = 99;
  htim3.Init.CounterMode = TIM_COUNTERMODE_UP;
  htim3.Init.Period = 15503;
  htim3.Init.ClockDivision = TIM_CLOCKDIVISION_DIV1;
  htim3.Init.AutoReloadPreload = TIM_AUTORELOAD_PRELOAD_ENABLE;
  if (HAL_TIM_PWM_Init(&htim3) != HAL_OK)
  {
    Error_Handler();
  }
  sMasterConfig.MasterOutputTrigger = TIM_TRGO_RESET;
  sMasterConfig.MasterSlaveMode = TIM_MASTERSLAVEMODE_DISABLE;
  if (HAL_TIMEx_MasterConfigSynchronization(&htim3, &sMasterConfig) != HAL_OK)
  {
    Error_Handler();
  }
  sConfigOC.OCMode = TIM_OCMODE_PWM1;
  sConfigOC.Pulse = 0;
  sConfigOC.OCPolarity = TIM_OCPOLARITY_HIGH;
  sConfigOC.OCFastMode = TIM_OCFAST_DISABLE;
  if (HAL_TIM_PWM_ConfigChannel(&htim3, &sConfigOC, TIM_CHANNEL_1) != HAL_OK)
  {
    Error_Handler();
  }
  if (HAL_TIM_PWM_ConfigChannel(&htim3, &sConfigOC, TIM_CHANNEL_2) != HAL_OK)
  {
    Error_Handler();
  }
  HAL_TIM_MspPostInit(&htim3);

}

static void MX_TIM5_Init(void)
{

  TIM_SlaveConfigTypeDef sSlaveConfig = {0};
  TIM_IC_InitTypeDef sConfigIC = {0};
  TIM_MasterConfigTypeDef sMasterConfig = {0};

  htim5.Instance = TIM5;
  htim5.Init.Prescaler = 0;
  htim5.Init.CounterMode = TIM_COUNTERMODE_UP;
  htim5.Init.Period = 4294967295;
  htim5.Init.ClockDivision = TIM_CLOCKDIVISION_DIV1;
  htim5.Init.AutoReloadPreload = TIM_AUTORELOAD_PRELOAD_DISABLE;
  if (HAL_TIM_IC_Init(&htim5) != HAL_OK)
  {
    Error_Handler();
  }
  sSlaveConfig.SlaveMode = TIM_SLAVEMODE_RESET;
  sSlaveConfig.InputTrigger = TIM_TS_TI1FP1;
  sSlaveConfig.TriggerPolarity = TIM_INPUTCHANNELPOLARITY_RISING;
  sSlaveConfig.TriggerPrescaler = TIM_ICPSC_DIV1;
  sSlaveConfig.TriggerFilter = 0;
  if (HAL_TIM_SlaveConfigSynchro(&htim5, &sSlaveConfig) != HAL_OK)
  {
    Error_Handler();
  }
  sConfigIC.ICPolarity = TIM_INPUTCHANNELPOLARITY_RISING;
  sConfigIC.ICSelection = TIM_ICSELECTION_DIRECTTI;
  sConfigIC.ICPrescaler = TIM_ICPSC_DIV1;
  sConfigIC.ICFilter = 0;
  if (HAL_TIM_IC_ConfigChannel(&htim5, &sConfigIC, TIM_CHANNEL_1) != HAL_OK)
  {
    Error_Handler();
  }
  sConfigIC.ICPolarity = TIM_INPUTCHANNELPOLARITY_FALLING;
  sConfigIC.ICSelection = TIM_ICSELECTION_INDIRECTTI;
  if (HAL_TIM_IC_ConfigChannel(&htim5, &sConfigIC, TIM_CHANNEL_2) != HAL_OK)
  {
    Error_Handler();
  }
  sMasterConfig.MasterOutputTrigger = TIM_TRGO_RESET;
  sMasterConfig.MasterSlaveMode = TIM_MASTERSLAVEMODE_DISABLE;
  if (HAL_TIMEx_MasterConfigSynchronization(&htim5, &sMasterConfig) != HAL_OK)
  {
    Error_Handler();
  }

}

static void MX_TIM7_Init(void)
{

  TIM_MasterConfigTypeDef sMasterConfig = {0};

  htim7.Instance = TIM7;
  htim7.Init.Prescaler = 9999;
  htim7.Init.CounterMode = TIM_COUNTERMODE_UP;
  htim7.Init.Period = 999;
  htim7.Init.AutoReloadPreload = TIM_AUTORELOAD_PRELOAD_ENABLE;
  if (HAL_TIM_Base_Init(&htim7) != HAL_OK)
  {
    Error_Handler();
  }
  sMasterConfig.MasterOutputTrigger = TIM_TRGO_RESET;
  sMasterConfig.MasterSlaveMode = TIM_MASTERSLAVEMODE_DISABLE;
  if (HAL_TIMEx_MasterConfigSynchronization(&htim7, &sMasterConfig) != HAL_OK)
  {
    Error_Handler();
  }

}

static void MX_TIM15_Init(void)
{

  TIM_SlaveConfigTypeDef sSlaveConfig = {0};
  TIM_IC_InitTypeDef sConfigIC = {0};
  TIM_MasterConfigTypeDef sMasterConfig = {0};

  htim15.Instance = TIM15;
  htim15.Init.Prescaler = 0;
  htim15.Init.CounterMode = TIM_COUNTERMODE_UP;
  htim15.Init.Period = 65535;
  htim15.Init.ClockDivision = TIM_CLOCKDIVISION_DIV1;
  htim15.Init.RepetitionCounter = 0;
  htim15.Init.AutoReloadPreload = TIM_AUTORELOAD_PRELOAD_DISABLE;
  if (HAL_TIM_IC_Init(&htim15) != HAL_OK)
  {
    Error_Handler();
  }
  sSlaveConfig.SlaveMode = TIM_SLAVEMODE_RESET;
  sSlaveConfig.InputTrigger = TIM_TS_TI1FP1;
  sSlaveConfig.TriggerPolarity = TIM_INPUTCHANNELPOLARITY_RISING;
  sSlaveConfig.TriggerPrescaler = TIM_ICPSC_DIV1;
  sSlaveConfig.TriggerFilter = 0;
  if (HAL_TIM_SlaveConfigSynchro(&htim15, &sSlaveConfig) != HAL_OK)
  {
    Error_Handler();
  }
  sConfigIC.ICPolarity = TIM_INPUTCHANNELPOLARITY_RISING;
  sConfigIC.ICSelection = TIM_ICSELECTION_DIRECTTI;
  sConfigIC.ICPrescaler = TIM_ICPSC_DIV1;
  sConfigIC.ICFilter = 0;
  if (HAL_TIM_IC_ConfigChannel(&htim15, &sConfigIC, TIM_CHANNEL_1) != HAL_OK)
  {
    Error_Handler();
  }
  sConfigIC.ICPolarity = TIM_INPUTCHANNELPOLARITY_FALLING;
  sConfigIC.ICSelection = TIM_ICSELECTION_INDIRECTTI;
  if (HAL_TIM_IC_ConfigChannel(&htim15, &sConfigIC, TIM_CHANNEL_2) != HAL_OK)
  {
    Error_Handler();
  }
  sMasterConfig.MasterOutputTrigger = TIM_TRGO_RESET;
  sMasterConfig.MasterSlaveMode = TIM_MASTERSLAVEMODE_DISABLE;
  if (HAL_TIMEx_MasterConfigSynchronization(&htim15, &sMasterConfig) != HAL_OK)
  {
    Error_Handler();
  }

}

static void MX_TIM16_Init(void)
{

  htim16.Instance = TIM16;
  htim16.Init.Prescaler = 9999;
  htim16.Init.CounterMode = TIM_COUNTERMODE_UP;
  htim16.Init.Period = 499;
  htim16.Init.ClockDivision = TIM_CLOCKDIVISION_DIV1;
  htim16.Init.RepetitionCounter = 0;
  htim16.Init.AutoReloadPreload = TIM_AUTORELOAD_PRELOAD_ENABLE;
  if (HAL_TIM_Base_Init(&htim16) != HAL_OK)
  {
    Error_Handler();
  }

}

static void MX_USB_OTG_FS_PCD_Init(void)
{

  hpcd_USB_OTG_FS.Instance = USB_OTG_FS;
  hpcd_USB_OTG_FS.Init.dev_endpoints = 9;
  hpcd_USB_OTG_FS.Init.speed = PCD_SPEED_FULL;
  hpcd_USB_OTG_FS.Init.dma_enable = DISABLE;
  hpcd_USB_OTG_FS.Init.phy_itface = PCD_PHY_EMBEDDED;
  hpcd_USB_OTG_FS.Init.Sof_enable = DISABLE;
  hpcd_USB_OTG_FS.Init.low_power_enable = DISABLE;
  hpcd_USB_OTG_FS.Init.lpm_enable = DISABLE;
  hpcd_USB_OTG_FS.Init.battery_charging_enable = DISABLE;
  hpcd_USB_OTG_FS.Init.vbus_sensing_enable = DISABLE;
  hpcd_USB_OTG_FS.Init.use_dedicated_ep1 = DISABLE;
  if (HAL_PCD_Init(&hpcd_USB_OTG_FS) != HAL_OK)
  {
    Error_Handler();
  }

}

static void MX_BDMA_Init(void)
{

  /* DMA controller clock enable */
  __HAL_RCC_BDMA_CLK_ENABLE();

  /* DMA interrupt init */
  /* BDMA_Channel0_IRQn interrupt configuration */
  HAL_NVIC_SetPriority(BDMA_Channel0_IRQn, 0, 0);
  HAL_NVIC_EnableIRQ(BDMA_Channel0_IRQn);

}

static void MX_DMA_Init(void)
{

  /* DMA controller clock enable */
  __HAL_RCC_DMA1_CLK_ENABLE();

  /* DMA interrupt init */
  /* DMA1_Stream0_IRQn interrupt configuration */
  HAL_NVIC_SetPriority(DMA1_Stream0_IRQn, 0, 0);
  HAL_NVIC_EnableIRQ(DMA1_Stream0_IRQn);
  /* DMA1_Stream1_IRQn interrupt configuration */
  HAL_NVIC_SetPriority(DMA1_Stream1_IRQn, 0, 0);
  HAL_NVIC_EnableIRQ(DMA1_Stream1_IRQn);
  /* DMA1_Stream2_IRQn interrupt configuration */
  HAL_NVIC_SetPriority(DMA1_Stream2_IRQn, 0, 0);
  HAL_NVIC_EnableIRQ(DMA1_Stream2_IRQn);
  /* DMA1_Stream3_IRQn interrupt configuration */
  HAL_NVIC_SetPriority(DMA1_Stream3_IRQn, 0, 0);
  HAL_NVIC_EnableIRQ(DMA1_Stream3_IRQn);
  /* DMA1_Stream4_IRQn interrupt configuration */
  HAL_NVIC_SetPriority(DMA1_Stream4_IRQn, 0, 0);
  HAL_NVIC_EnableIRQ(DMA1_Stream4_IRQn);

}

static void MX_GPIO_Init(void)
{
  GPIO_InitTypeDef GPIO_InitStruct = {0};

  /* GPIO Ports Clock Enable */
  __HAL_RCC_GPIOE_CLK_ENABLE();
  __HAL_RCC_GPIOC_CLK_ENABLE();
  __HAL_RCC_GPIOH_CLK_ENABLE();
  __HAL_RCC_GPIOA_CLK_ENABLE();
  __HAL_RCC_GPIOB_CLK_ENABLE();
  __HAL_RCC_GPIOD_CLK_ENABLE();

  /*Configure GPIO pin Output Level */
  HAL_GPIO_WritePin(GPIOE, ONBOARD_LED_Pin|LED_RED_Pin, GPIO_PIN_RESET);

  /*Configure GPIO pin Output Level */
  HAL_GPIO_WritePin(GPIOB, BNO_NRST_Pin|BNO_BOOTN_Pin|Manual_Output_Pin, GPIO_PIN_RESET);

  /*Configure GPIO pin Output Level */
  HAL_GPIO_WritePin(GPIOD, BNO_P0_Pin|BNO_P1_Pin|PCA9685_OE_Pin|LED_BLUE_Pin
                          |LED_YELLOW_Pin|SPI_CS_Pin, GPIO_PIN_RESET);

  /*Configure GPIO pins : ONBOARD_LED_Pin LED_RED_Pin */
  GPIO_InitStruct.Pin = ONBOARD_LED_Pin|LED_RED_Pin;
  GPIO_InitStruct.Mode = GPIO_MODE_OUTPUT_PP;
  GPIO_InitStruct.Pull = GPIO_NOPULL;
  GPIO_InitStruct.Speed = GPIO_SPEED_FREQ_LOW;
  HAL_GPIO_Init(GPIOE, &GPIO_InitStruct);

  /*Configure GPIO pin : Onboard_Key1_Pin */
  GPIO_InitStruct.Pin = Onboard_Key1_Pin;
  GPIO_InitStruct.Mode = GPIO_MODE_IT_RISING;
  GPIO_InitStruct.Pull = GPIO_NOPULL;
  HAL_GPIO_Init(Onboard_Key1_GPIO_Port, &GPIO_InitStruct);

  /*Configure GPIO pin : BNO_INT_Pin */
  GPIO_InitStruct.Pin = BNO_INT_Pin;
  GPIO_InitStruct.Mode = GPIO_MODE_IT_RISING;
  GPIO_InitStruct.Pull = GPIO_NOPULL;
  HAL_GPIO_Init(BNO_INT_GPIO_Port, &GPIO_InitStruct);

  /*Configure GPIO pins : BNO_NRST_Pin BNO_BOOTN_Pin Manual_Output_Pin */
  GPIO_InitStruct.Pin = BNO_NRST_Pin|BNO_BOOTN_Pin|Manual_Output_Pin;
  GPIO_InitStruct.Mode = GPIO_MODE_OUTPUT_PP;
  GPIO_InitStruct.Pull = GPIO_NOPULL;
  GPIO_InitStruct.Speed = GPIO_SPEED_FREQ_LOW;
  HAL_GPIO_Init(GPIOB, &GPIO_InitStruct);

  /*Configure GPIO pins : BNO_P0_Pin BNO_P1_Pin PCA9685_OE_Pin LED_BLUE_Pin
                           LED_YELLOW_Pin SPI_CS_Pin */
  GPIO_InitStruct.Pin = BNO_P0_Pin|BNO_P1_Pin|PCA9685_OE_Pin|LED_BLUE_Pin
                          |LED_YELLOW_Pin|SPI_CS_Pin;
  GPIO_InitStruct.Mode = GPIO_MODE_OUTPUT_PP;
  GPIO_InitStruct.Pull = GPIO_NOPULL;
  GPIO_InitStruct.Speed = GPIO_SPEED_FREQ_LOW;
  HAL_GPIO_Init(GPIOD, &GPIO_InitStruct);

  /*Configure GPIO pin : Manual_Input_Pin */
  GPIO_InitStruct.Pin = Manual_Input_Pin;
  GPIO_InitStruct.Mode = GPIO_MODE_INPUT;
  GPIO_InitStruct.Pull = GPIO_NOPULL;
  HAL_GPIO_Init(Manual_Input_GPIO_Port, &GPIO_InitStruct);

}

void Error_Handler(void)
{
  __disable_irq();
  while (1)
  {
  }
}
